AUTOSAR XML (schema 00045)
package /CscPlatform
  client server interface CSI_Time_GetTimeStampInfo
    4 x operation, all with fire-and-forget=false, possible-error=E_OK:
      GetGlobalTimeStatus
        arg status: type=uint8_t, direction=OUT, server-argument-impl-policy=USE-ARGUMENT-TYPE
      GetTimeStampMs
        arg ts_ms: type=uint64_t, direction=OUT, server-argument-impl-policy=USE-ARGUMENT-TYPE
      GetTimeStampNs
        arg ts_ns: type=uint64_t, direction=OUT, server-argument-impl-policy=USE-ARGUMENT-TYPE
      GetTimeStampSec
        arg ts_sec: type=uint64_t, direction=OUT, server-argument-impl-policy=USE-ARGUMENT-TYPE
    error E_OK: error-code=0
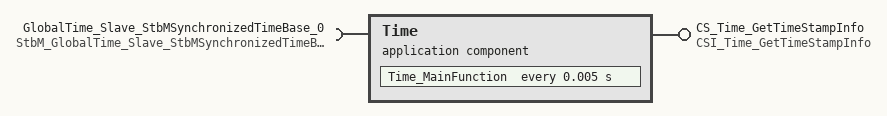
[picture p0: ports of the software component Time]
  application sw component type Time
    provide port CS_Time_GetTimeStampInfo: provided-interface=CSI_Time_GetTimeStampInfo
    require port GlobalTime_Slave_StbMSynchronizedTimeBase_0: required-interface=StbM_GlobalTime_Slave_StbMSynchronizedTimeBase_0
    behavior Time_IB: handle-termination-and-restart=NO-SUPPORT
      4 x operation invoked event:
        GetGlobalTimeStatus_Event: start-on-event=Time_GetGlobalTimeStatus, operation=CS_Time_GetTimeStampInfo.GetGlobalTimeStatus
        GetTimeStampMs_Event: start-on-event=Time_GetTimeStampMs, operation=CS_Time_GetTimeStampInfo.GetTimeStampMs
        GetTimeStampNs_Event: start-on-event=Time_GetTimeStampNs, operation=CS_Time_GetTimeStampInfo.GetTimeStampNs
        GetTimeStampSec_Event: start-on-event=Time_GetTimeStampSec, operation=CS_Time_GetTimeStampInfo.GetTimeStampSec
      init event InitEvent_Time_InitFunction: start-on-event=Time_InitFunction
      timing event TimingEvent_Time_MainFunction: start-on-event=Time_MainFunction, period=0.005
      6 x runnable:
        Time_GetGlobalTimeStatus
        Time_GetTimeStampMs
        Time_GetTimeStampNs
        Time_GetTimeStampSec
        Time_InitFunction
        Time_MainFunction
          sync call scp_GetCurrentTime: operation=GlobalTime_Slave_StbMSynchronizedTimeBase_0.GetCurrentTime, timeout=0.0
          sync call scp_GetRateDeviation: operation=GlobalTime_Slave_StbMSynchronizedTimeBase_0.GetRateDeviation, timeout=0.0
          sync call scp_GetTimeBaseStatus: operation=GlobalTime_Slave_StbMSynchronizedTimeBase_0.GetTimeBaseStatus, timeout=0.0
  swc implementation TimeImpl: programming-language=C, sw-version=0.0.1, vendor-id=0, behavior=Time_IB
    code-descriptors:
      code CodeGen: artifact-descriptors=[{short-label=SWSRC, category=SWSRC}, {short-label=SWHDR, category=SWHDR}]
    resource consumption Resource
      memory section CODE: sw-addrmethod=CODE
      memory section VAR_UNSPECIFIED: sw-addrmethod=VAR
